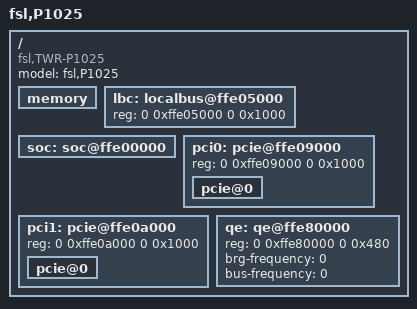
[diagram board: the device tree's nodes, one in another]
/include/ "p1021si-pre.dtsi"
/ {
	model = "fsl,P1025";
	compatible = "fsl,TWR-P1025";
	memory {
		device_type = "memory";
	};
	lbc: localbus@ffe05000 {
		reg = <0 0xffe05000 0 0x1000>;
		ranges = <0x0 0x0 0x0 0xec000000 0x04000000
			  0x2 0x0 0x0 0xe0000000 0x00020000>;
	};
	soc: soc@ffe00000 {
		ranges = <0x0 0x0 0xffe00000 0x100000>;
	};
	pci0: pcie@ffe09000 {
		ranges = <0x2000000 0x0 0xa0000000 0 0xa0000000 0x0 0x20000000
			  0x1000000 0x0 0x00000000 0 0xffc10000 0x0 0x10000>;
		reg = <0 0xffe09000 0 0x1000>;
		pcie@0 {
			ranges = <0x2000000 0x0 0xa0000000
				  0x2000000 0x0 0xa0000000
				  0x0 0x20000000
				  0x1000000 0x0 0x0
				  0x1000000 0x0 0x0
				  0x0 0x100000>;
		};
	};
	pci1: pcie@ffe0a000 {
		reg = <0 0xffe0a000 0 0x1000>;
		ranges = <0x2000000 0x0 0x80000000 0 0x80000000 0x0 0x20000000
			  0x1000000 0x0 0x00000000 0 0xffc00000 0x0 0x10000>;
		pcie@0 {
			ranges = <0x2000000 0x0 0x80000000
				  0x2000000 0x0 0x80000000
				  0x0 0x20000000
				  0x1000000 0x0 0x0
				  0x1000000 0x0 0x0
				  0x0 0x100000>;
		};
	};
	qe: qe@ffe80000 {
		ranges = <0x0 0x0 0xffe80000 0x40000>;
		reg = <0 0xffe80000 0 0x480>;
		brg-frequency = <0>;
		bus-frequency = <0>;
	};
};
/include/ "p1025twr.dtsi"
/include/ "p1021si-post.dtsi"
